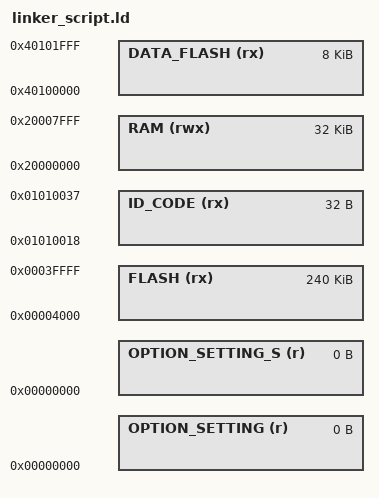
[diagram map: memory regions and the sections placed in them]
RAM_START = 0x20000000;
RAM_LENGTH = 0x8000;
FLASH_START = 0x00000000;
FLASH_LENGTH = 0x40000;
DATA_FLASH_START = 0x40100000;
DATA_FLASH_LENGTH = 0x2000;
OPTION_SETTING_START = 0x00000000;
OPTION_SETTING_LENGTH = 0x0;
OPTION_SETTING_S_START = 0x00000000;
OPTION_SETTING_S_LENGTH = 0x0;
ID_CODE_START = 0x01010018;
ID_CODE_LENGTH = 0x20;
SDRAM_START = 0x90000000;
SDRAM_LENGTH = 0x0;
QSPI_FLASH_START = 0x60000000;
QSPI_FLASH_LENGTH = 0x0;
OSPI_DEVICE_0_START = 0x68000000;
OSPI_DEVICE_0_LENGTH = 0x0;
OSPI_DEVICE_1_START = 0x70000000;
OSPI_DEVICE_1_LENGTH = 0x0;
FLASH_IMAGE_START = 0x4000;
VECTOR_TABLE_LENGTH = 0x100;
BSP_CFG_STACK_MAIN_BYTES = 0x400;

MEMORY
{
  FLASH (rx)      : ORIGIN = FLASH_IMAGE_START, LENGTH = FLASH_LENGTH - FLASH_IMAGE_START
  RAM (rwx)       : ORIGIN = RAM_START, LENGTH = RAM_LENGTH
  DATA_FLASH (rx) : ORIGIN = DATA_FLASH_START, LENGTH = DATA_FLASH_LENGTH
  OPTION_SETTING (r): ORIGIN = OPTION_SETTING_START, LENGTH = OPTION_SETTING_LENGTH
  OPTION_SETTING_S (r): ORIGIN = OPTION_SETTING_S_START, LENGTH = OPTION_SETTING_S_LENGTH
  ID_CODE (rx)    : ORIGIN = ID_CODE_START, LENGTH = ID_CODE_LENGTH
}
